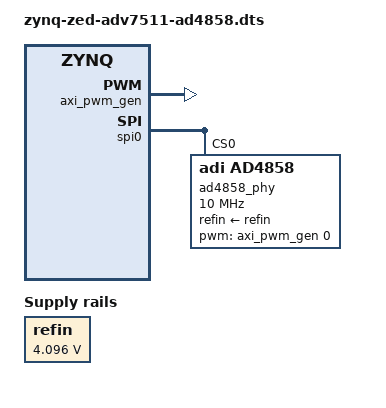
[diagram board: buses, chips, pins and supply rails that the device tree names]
// SPDX-License-Identifier: GPL-2.0
/dts-v1/;

#include "zynq-zed.dtsi"
#include "zynq-zed-adv7511.dtsi"
#include <dt-bindings/pwm/pwm.h>

/ {

	refin: regulator-vref {
		compatible = "regulator-fixed";
		regulator-name = "fixed-supply";
		regulator-min-microvolt = <4096000>;
		regulator-max-microvolt = <4096000>;
		regulator-always-on;
	};
};

&fpga_axi {
	rx_dma: dmac@43E00000 {
		compatible = "adi,axi-dmac-1.00.a";
		reg = <0x43E00000 0x1000>;
		#dma-cells = <1>;
		interrupt-parent = <&intc>;
		interrupts = <0 54 IRQ_TYPE_LEVEL_HIGH>;
		clocks = <&clkc 15>;

		adi,channels {
			#size-cells = <0>;
			#address-cells = <1>;

			dma-channel@0 {
				reg = <0>;
				adi,source-bus-width = <256>;
				adi,source-bus-type = <2>;
				adi,destination-bus-width = <64>;
				adi,destination-bus-type = <0>;
			};
		};
	};

	ref_clk: clk@0x44000000 {
		compatible = "adi,axi-clkgen-2.00.a";
		reg = <0x44000000 0x10000>;
		#clock-cells = <0>;
		clocks = <&clkc 15>, <&clkc 16>;
		clock-names = "s_axi_aclk", "clkin1";
		clock-output-names = "ref_clk";
	};

	axi_pwm_gen: pwm@0x43d00000 {
		compatible = "adi,axi-pwmgen";
		reg = <0x43d00000 0x1000>;
		label = "cnv";
		#pwm-cells = <2>;
		clocks = <&ref_clk>;
	};

	ad4858@0x43c00000 {
		compatible = "adi,axi-adc-10.0.a";
		reg = <0x43c00000 0x10000>;
		dmas = <&rx_dma 0>;
		dma-names = "rx";
		spibus-connected = <&ad4858_phy>;
	};
};

&spi0 {
	status = "okay";

	ad4858_phy: adc@0{
		compatible = "adi,ad4858";
		reg = <0>;
		spi-max-frequency = <10000000>;
		refin-supply = <&refin>;
		clocks = <&ref_clk>;
		clock-names = "scki";
		dmas = <&rx_dma 0>;
		dma-names = "rx";
		pwms = <&axi_pwm_gen 0 0>;
		pwm-names = "cnv";
	};
};
